VERSION ""

NS_ :

BS_:

BU_: CLUSTER INVERTER

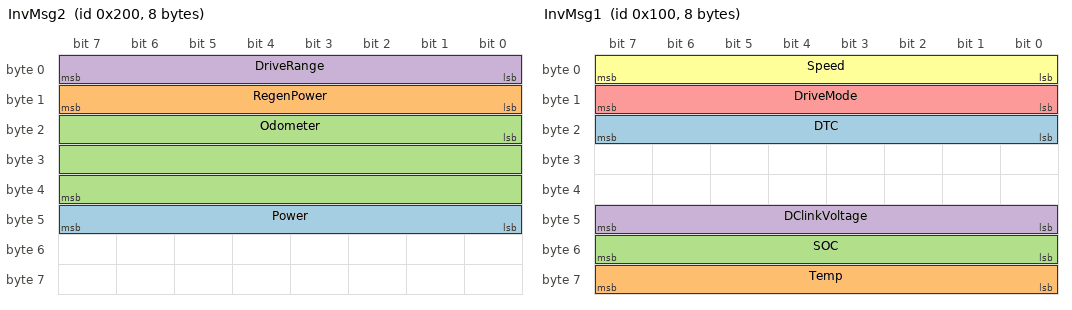
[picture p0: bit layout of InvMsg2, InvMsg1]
BO_ 512 InvMsg2: 8 INVERTER
 SG_ Power : 40|8@1+ (1,0) [0|255] "kW"  CLUSTER
 SG_ RegenPower : 8|8@1+ (1,0) [0|255] "kW"  CLUSTER
 SG_ Odometer : 16|24@1+ (1,0) [0|16777215] ""  CLUSTER
 SG_ DriveRange : 0|8@1+ (1,0) [0|255] "km"  CLUSTER

BO_ 256 InvMsg1: 8 INVERTER
 SG_ DTC : 16|8@1+ (1,0) [0|255] ""  CLUSTER
 SG_ Temp : 56|8@1+ (1,-20) [-20|235] "degC"  CLUSTER
 SG_ SOC : 48|8@1+ (1,0) [0|100] "%"  CLUSTER
 SG_ DClinkVoltage : 40|8@1+ (1,0) [0|80] "V"  CLUSTER
 SG_ DriveMode : 8|8@1+ (1,0) [0|3] ""  CLUSTER
 SG_ Speed : 0|8@1+ (1,-10) [-10|245] "km/h"  CLUSTER

EV_ EnvKlemme30: 0 [0|1] "" 1 1 DUMMY_NODE_VECTOR0 Vector__XXX;

EV_ EnvKlemme15: 0 [0|1] "" 0 2 DUMMY_NODE_VECTOR0 Vector__XXX;

BA_DEF_ BU_  "NodeLayerModules" STRING ;
BA_DEF_ BO_  "GenMsgILSupport" ENUM  "No","Yes";
BA_DEF_  "NmBaseAddress" HEX 1024 1087;
BA_DEF_  "BusType" STRING ;
BA_DEF_ BO_  "GenMsgCycleTime" INT 0 50000;
BA_DEF_ BO_  "GenMsgSendType" ENUM  "Cyclic","NotUsed","NotUsed","NotUsed","NotUsed","NotUsed","NotUsed","IfActive","NoMsgSendType","NotUsed","vector_leerstring";
BA_DEF_ SG_  "GenSigSendType" ENUM  "Cyclic","OnWrite","OnWriteWithRepetition","OnChange","OnChangeWithRepetition","IfActive","IfActiveWithRepetition","NoSigSendType","NotUsed","NotUsed","NotUsed","NotUsed","NotUsed";
BA_DEF_ SG_  "GenSigStartValue" FLOAT 0 100000000000;
BA_DEF_DEF_  "NodeLayerModules" "CANoeILNLVector.dll";
BA_DEF_DEF_  "GenMsgILSupport" "Yes";
BA_DEF_DEF_  "NmBaseAddress" 1024;
BA_DEF_DEF_  "BusType" "";
BA_DEF_DEF_  "GenMsgCycleTime" 0;
BA_DEF_DEF_  "GenMsgSendType" "NoMsgSendType";
BA_DEF_DEF_  "GenSigSendType" "Cyclic";
BA_DEF_DEF_  "GenSigStartValue" 0;
BA_ "BusType" "CAN";
BA_ "GenMsgCycleTime" BO_ 512 200;
BA_ "GenMsgCycleTime" BO_ 256 100;
BA_ "GenSigStartValue" SG_ 256 Temp 20;
BA_ "GenSigStartValue" SG_ 256 Speed 10;
VAL_ 256 DriveMode 0 "P" 1 "R" 2 "N" 3 "D" ;

CM_ "2026-07-31: 차량단(인버터) 설계가 아직 끝나지 않아, 이 프로젝트가 CAN 스펙을 먼저
정하고 인버터 쪽이 여기 맞추기로 함(사용자 확인) — 즉 이 파일은 더 이상 '실차값 추측'이
아니라 저희가 직접 정의한 스펙이다. Desktop의 cluster.dbc가 원본이고 이 파일은 그 사본
(main/twai.c/vehicle_data.h를 이 파일 기준으로 맞춤). InvMsg1(0x100)/InvMsg2(0x200)
2개 메시지에 10개 신호를 패킹했다 (이전 리비전엔 신호당 메시지 1개씩 총 10개 ID를 썼음).
Reserved 바이트(InvMsg1의 byte3~4, InvMsg2의 byte6~7)는 DBC 문법상 signal 없인 표현이
안 돼 이 파일엔 안 보이지만 실제로 비어있다 — main/twai.c 주석 참고. 인버터 쪽 실물
구현/실기 검증 전이므로 '스펙을 정했다' != '실물로 확인됐다'는 여전히 유효하다.";
CM_ BO_ 256 "Speed/DriveMode처럼 빠르게 갱신돼야 하는 값과 SOC/Temp/DTC/DClinkVoltage처럼
느려도 되는 값이 한 메시지에 섞여있어, GenMsgCycleTime을 더 빠른 쪽(Speed) 기준인
100ms로 잡음.";
CM_ BO_ 512 "DriveRange/RegenPower/Odometer/Power — InvMsg1보다 느리게 변하는 값들이라
GenMsgCycleTime 200ms.";
